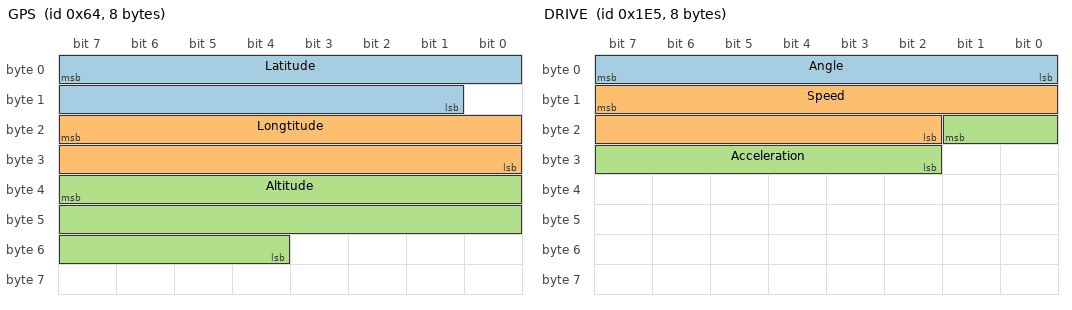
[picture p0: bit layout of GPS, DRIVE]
BO_ 100 GPS: 8 Vector__XXX
	SG_ Latitude : 7|15@0+ (0.01,-90) [-90|90] "" Vector__XXX
	SG_ Longtitude : 23|16@0+ (0.01,-180) [-180|180] "" Vector__XXX
	SG_ Altitude : 39|20@0+ (0.01,-1000) [-1000|9000] "" Vector__XXX
BO_ 485 DRIVE: 8 Vector__XXX
	SG_ Angle : 7|8@0+ (1,0) [0|180] "" Vector__XXX
	SG_ Speed : 15|14@0+ (0.01,0) [0|120] "" Vector__XXX
	SG_ Acceleration : 17|8@0+ (0.01,-1) [-1|1] "" Vector__XXX
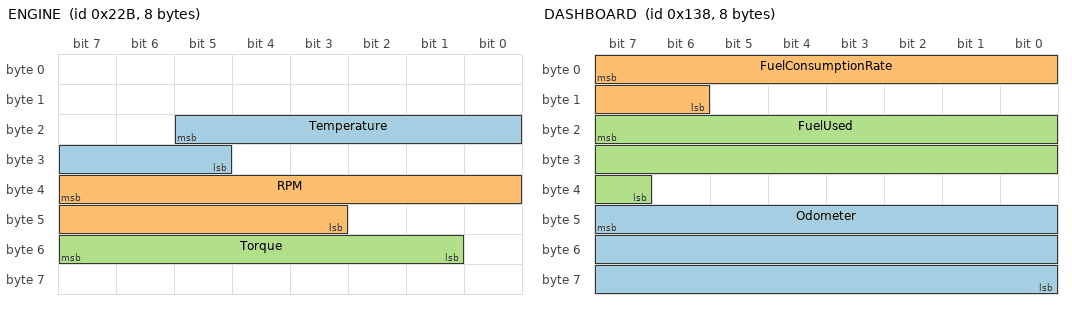
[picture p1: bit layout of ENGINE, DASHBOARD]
BO_ 555 ENGINE: 8 Vector__XXX
	SG_ Temperature : 21|9@0+ (1,-20) [-20|300] "" Vector__XXX
	SG_ RPM : 39|13@0+ (1,0) [0|6000] "" Vector__XXX
	SG_ Torque : 55|7@0+ (1,0) [0|0] "" Vector__XXX
BO_ 423 PEDAL: 8 Vector__XXX
	SG_ AcceleratorOpeningAngel : 15|14@0+ (0.01,0) [0|100] "" Vector__XXX
	SG_ BrakePosition : 31|14@0+ (0.01,0) [0|100] "" Vector__XXX
BO_ 312 DASHBOARD: 8 Vector__XXX
	SG_ Odometer : 47|24@0+ (1,0) [0|0] "" Vector__XXX
	SG_ FuelConsumptionRate : 7|10@0+ (0.01,0) [0|0] "" Vector__XXX
	SG_ FuelUsed : 23|17@0+ (1,0) [0|0] "" Vector__XXX
